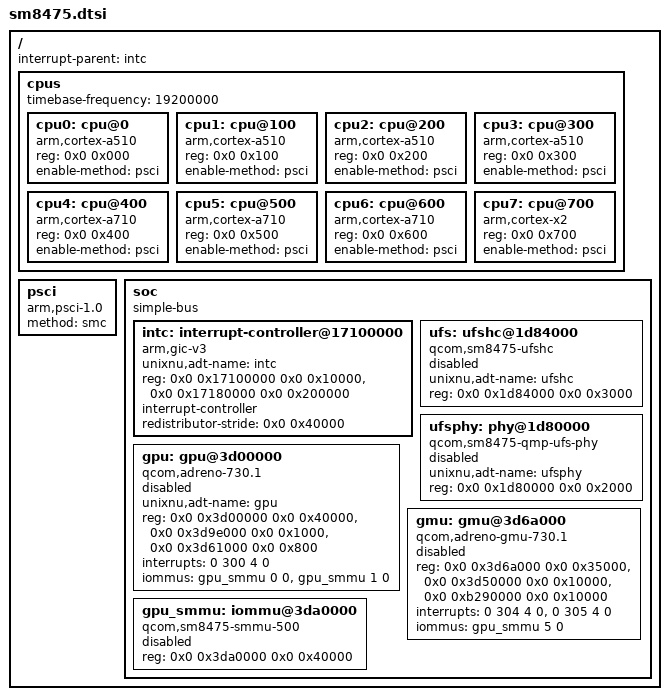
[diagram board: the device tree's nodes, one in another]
// SPDX-License-Identifier: BSD-2-Clause-Patent
// Shared Qualcomm SM8475 (Snapdragon 8+ Gen 1, cape) hardware description
// for UniXNU device repositories.
//
// Sources cross-checked:
//   - Mainline Linux arch/arm64/boot/dts/qcom/sm8450.dtsi (f1586048)
//   - Mainline Xiaomi Pad 6 Pro yzddmr6/linux-sm8450-liuqin
//   - Stock SM8475 cape vendor_boot DTB (socid 531 / 0x213)
//
// Rules:
//   - Board memory maps, reserved-memory, panel, touch and partitions belong
//     in the board DTS, never here.
//   - Peripheral nodes stay status = "disabled" until a board enables them.

/ {
    #address-cells = <2>;
    #size-cells = <2>;
    interrupt-parent = <&intc>;

    cpus {
        #address-cells = <2>;
        #size-cells = <0>;
        timebase-frequency = <19200000>;

        // 4x Cortex-A510 (E), 3x Cortex-A710 (P), 1x Cortex-X2 (P)
        // MPIDR Affinity1 = 0x000..0x700.
        cpu0: cpu@0 {
            device_type = "cpu";
            compatible = "arm,cortex-a510";
            reg = <0x0 0x000>;
            enable-method = "psci";
        };

        cpu1: cpu@100 {
            device_type = "cpu";
            compatible = "arm,cortex-a510";
            reg = <0x0 0x100>;
            enable-method = "psci";
        };

        cpu2: cpu@200 {
            device_type = "cpu";
            compatible = "arm,cortex-a510";
            reg = <0x0 0x200>;
            enable-method = "psci";
        };

        cpu3: cpu@300 {
            device_type = "cpu";
            compatible = "arm,cortex-a510";
            reg = <0x0 0x300>;
            enable-method = "psci";
        };

        cpu4: cpu@400 {
            device_type = "cpu";
            compatible = "arm,cortex-a710";
            reg = <0x0 0x400>;
            enable-method = "psci";
        };

        cpu5: cpu@500 {
            device_type = "cpu";
            compatible = "arm,cortex-a710";
            reg = <0x0 0x500>;
            enable-method = "psci";
        };

        cpu6: cpu@600 {
            device_type = "cpu";
            compatible = "arm,cortex-a710";
            reg = <0x0 0x600>;
            enable-method = "psci";
        };

        cpu7: cpu@700 {
            device_type = "cpu";
            compatible = "arm,cortex-x2";
            reg = <0x0 0x700>;
            enable-method = "psci";
        };
    };

    psci {
        compatible = "arm,psci-1.0";
        method = "smc";
    };

    soc: soc {
        compatible = "simple-bus";
        #address-cells = <2>;
        #size-cells = <2>;
        ranges;

        // GICv3 distributor + redistributors (256 KiB stride)
        intc: interrupt-controller@17100000 {
            compatible = "arm,gic-v3";
            unixnu,adt-name = "intc";
            reg = <0x0 0x17100000 0x0 0x10000>,
                  <0x0 0x17180000 0x0 0x200000>;
            #interrupt-cells = <4>;
            #address-cells = <0>;
            interrupt-controller;
            redistributor-stride = <0x0 0x40000>;
        };

        // UFS 3.1 host controller (SM8475 cape)
        // Note: Omit `interrupts` from the exported ADT node (matching sm8550.dtsi):
        // devicetree.py emits `phandle` rather than `AAPL,phandle`, so an exported
        // `interrupts` property causes XNU's IODTFindInterruptParent() to return NULL
        // and data-abort in IODTGetICellCounts().
        ufs: ufshc@1d84000 {
            compatible = "qcom,sm8475-ufshc", "qcom,ufshc", "jedec,ufs-2.0";
            unixnu,adt-name = "ufshc";
            reg = <0x0 0x1d84000 0x0 0x3000>;
            status = "disabled";
        };

        // SM8475 QMP UFS PHY (cape uses 0x1d80000, distinct from SM8450 0x1d87000)
        ufsphy: phy@1d80000 {
            compatible = "qcom,sm8475-qmp-ufs-phy";
            unixnu,adt-name = "ufsphy";
            reg = <0x0 0x1d80000 0x0 0x2000>;
            status = "disabled";
        };

        // Adreno 730 GPU (kept disabled until Adreno 730 provider lands)
        gpu: gpu@3d00000 {
            compatible = "qcom,adreno-730.1", "qcom,adreno";
            unixnu,adt-name = "gpu";
            reg = <0x0 0x3d00000 0x0 0x40000>,
                  <0x0 0x3d9e000 0x0 0x1000>,
                  <0x0 0x3d61000 0x0 0x800>;
            reg-names = "kgsl_3d0_reg_memory", "cx_mem", "cx_dbgc";
            interrupts = <0 300 4 0>;
            iommus = <&gpu_smmu 0 0>, <&gpu_smmu 1 0>;
            status = "disabled";
        };

        // SM8475 GMU (third window is 0xb290000, distinct from SM8550 0xb280000)
        gmu: gmu@3d6a000 {
            compatible = "qcom,adreno-gmu-730.1", "qcom,adreno-gmu";
            reg = <0x0 0x3d6a000 0x0 0x35000>,
                  <0x0 0x3d50000 0x0 0x10000>,
                  <0x0 0xb290000 0x0 0x10000>;
            reg-names = "gmu", "rscc", "gmu_pdc";
            interrupts = <0 304 4 0>, <0 305 4 0>;
            interrupt-names = "hfi", "gmu";
            iommus = <&gpu_smmu 5 0>;
            status = "disabled";
        };

        gpu_smmu: iommu@3da0000 {
            compatible = "qcom,sm8475-smmu-500", "qcom,adreno-smmu", "qcom,smmu-500", "arm,mmu-500";
            reg = <0x0 0x3da0000 0x0 0x40000>;
            #iommu-cells = <2>;
            status = "disabled";
        };
    };
};
